VERSION "dbc-export 1 2026.26.6.5"

NS_ :

BS_:

BU_: ADSP APB APP APS APSB BB BMS CC CMP CMPD CP DAS DI DIF DIR DPB EPAS3P EPAS3S EPASTP EPASTS EPBL EPBR ESP EVSE FC GTW HCML HCMR HVP IBST ICR IDB LS OCS1P PARK PCS PCS2 PM PMF PMR PNCD PTC RADC RCM RCM2 RCM3 RCU SCCM SCM SCS SDCR TAS TCU TCU2 TPMS TRCM UI UIS UMC USM V2G VC VCBATT VCBATT0 VCBATT1 VCBATT2 VCCC VCFRONT VCFRONT1 VCFRONT2 VCLEFT VCRIGHT VCSEAT2L VCSEAT2R VCSEC VEH

BO_ 505 VCSEC_requests: 8 VCSEC
 SG_ VCSEC_chargePortRequest : 0|2@1+ (1,0) [0|3] "" Vector__XXX
 SG_ VCSEC_presentHandles : 4|1@1+ (1,0) [0|1] "" Vector__XXX
 SG_ VCSEC_frontLeftClosureRequest : 5|3@1+ (1,0) [0|7] "" Vector__XXX
 SG_ VCSEC_frontRightClosureRequest : 8|3@1+ (1,0) [0|7] "" Vector__XXX
 SG_ VCSEC_rearLeftClosureRequest : 11|3@1+ (1,0) [0|7] "" Vector__XXX
 SG_ VCSEC_rearRightClosureRequest : 14|3@1+ (1,0) [0|7] "" Vector__XXX
 SG_ VCSEC_rearTrunkClosureRequest : 17|3@1+ (1,0) [0|7] "" Vector__XXX
 SG_ VCSEC_frontLeftRequestReason : 20|3@1+ (1,0) [0|7] "" Vector__XXX
 SG_ VCSEC_frontRightRequestReason : 23|3@1+ (1,0) [0|7] "" Vector__XXX
 SG_ VCSEC_rearLeftRequestReason : 26|3@1+ (1,0) [0|7] "" Vector__XXX
 SG_ VCSEC_rearRightRequestReason : 29|3@1+ (1,0) [0|7] "" Vector__XXX
 SG_ VCSEC_rearTrunkRequestReason : 32|3@1+ (1,0) [0|7] "" Vector__XXX
 SG_ VCSEC_rdMapDumpRequested : 35|1@1+ (1,0) [0|1] "" Vector__XXX
 SG_ VCSEC_driveAttemptedWithoutAuth : 36|4@1+ (1,0) [0|15] "" Vector__XXX
 SG_ VCSEC_closeAllStatus : 41|2@1+ (1,0) [0|3] "" Vector__XXX
 SG_ VCSEC_snapshotRequested : 43|4@1+ (1,0) [0|15] "" Vector__XXX
 SG_ VCSEC_chargeportRequestReason : 47|3@1+ (1,0) [0|7] "" Vector__XXX
 SG_ VCSEC_frontTrunkClosureRequest : 51|3@1+ (1,0) [0|7] "" Vector__XXX
 SG_ VCSEC_frontTrunkRequestReason : 54|3@1+ (1,0) [0|7] "" Vector__XXX

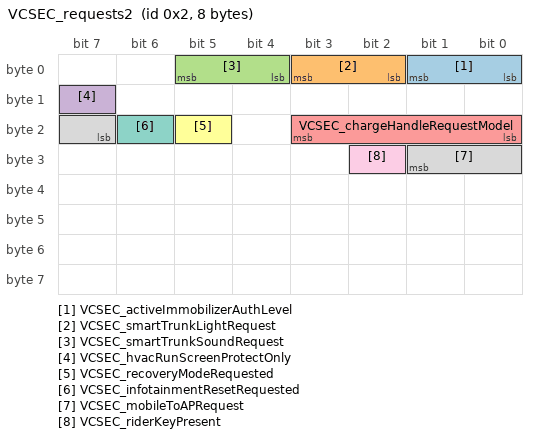
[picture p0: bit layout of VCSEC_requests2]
BO_ 2 VCSEC_requests2: 8 VCSEC
 SG_ VCSEC_activeImmobilizerAuthLevel : 0|2@1+ (1,0) [0|3] "" Vector__XXX
 SG_ VCSEC_smartTrunkLightRequest : 2|2@1+ (1,0) [0|3] "" Vector__XXX
 SG_ VCSEC_smartTrunkSoundRequest : 4|2@1+ (1,0) [0|3] "" Vector__XXX
 SG_ VCSEC_hvacRunScreenProtectOnly : 15|1@1+ (1,0) [0|1] "" Vector__XXX
 SG_ VCSEC_chargeHandleRequestModel : 16|4@1+ (1,0) [0|15] "" Vector__XXX
 SG_ VCSEC_recoveryModeRequested : 21|1@1+ (1,0) [0|1] "" Vector__XXX
 SG_ VCSEC_infotainmentResetRequested : 22|1@1+ (1,0) [0|1] "" Vector__XXX
 SG_ VCSEC_mobileToAPRequest : 23|3@1+ (1,0) [0|7] "" Vector__XXX
 SG_ VCSEC_riderKeyPresent : 26|1@1+ (1,0) [0|1] "" Vector__XXX

BO_ 1850 VC_LVBMS_brickMeasurements: 8 VC
 SG_ VC_LVBMS_brickMeasurementsMultip M : 0|6@1+ (1,0) [0|63] "" Vector__XXX
 SG_ VC_LVBMS_brickVoltage1 m0 : 8|13@1+ (0.001,0) [0|6.535] "V" Vector__XXX
 SG_ VC_LVBMS_brickVoltage2 m0 : 24|13@1+ (0.001,0) [0|6.535] "V" Vector__XXX
 SG_ VC_LVBMS_brickVoltage3 m0 : 37|13@1+ (0.001,0) [0|6.535] "V" Vector__XXX
 SG_ VC_LVBMS_brickVoltage4 m0 : 50|13@1+ (0.001,0) [0|6.535] "V" Vector__XXX
 SG_ VC_LVBMS_brickBalancingAh1 m1 : 8|24@1+ (0.001,0) [0|16777.214] "Ah" Vector__XXX
 SG_ VC_LVBMS_brickBalancingAh2 m1 : 32|24@1+ (0.001,0) [0|16777.214] "Ah" Vector__XXX
 SG_ VC_LVBMS_brickBalancingState1 m1 : 56|1@1+ (1,0) [0|1] "" Vector__XXX
 SG_ VC_LVBMS_brickBalancingState2 m1 : 57|1@1+ (1,0) [0|1] "" Vector__XXX
 SG_ VC_LVBMS_brickBalancingAh3 m2 : 8|24@1+ (0.001,0) [0|16777.214] "Ah" Vector__XXX
 SG_ VC_LVBMS_brickBalancingAh4 m2 : 32|24@1+ (0.001,0) [0|16777.214] "Ah" Vector__XXX
 SG_ VC_LVBMS_brickBalancingState3 m2 : 56|1@1+ (1,0) [0|1] "" Vector__XXX
 SG_ VC_LVBMS_brickBalancingState4 m2 : 57|1@1+ (1,0) [0|1] "" Vector__XXX

BO_ 1655 VC_LVBMS_statusHigh: 8 VC
 SG_ VC_lvbmsStatusHighIndex M : 0|3@1+ (1,0) [0|7] "" Vector__XXX
 SG_ VC_LVBMS_packCurrent m0 : 3|22@1+ (0.001,-2000) [-2000|2194.302] "A" Vector__XXX
 SG_ VC_LVBMS_packVoltage m0 : 25|16@1+ (0.001,0) [0|65.534] "V" Vector__XXX
 SG_ VC_LVBMS_packTemperature m0 : 41|9@1+ (0.5,-50) [-50|205] "degC" Vector__XXX
 SG_ VC_LVBMS_MOSTemperature m0 : 50|12@1+ (0.5,-50) [-50|1997] "degC" Vector__XXX
 SG_ VC_LVBMS_sumCellVoltage m1 : 8|16@1+ (0.001,0) [0|65.534] "V" Vector__XXX
 SG_ VC_LVBMS_maxBrickVoltage m1 : 24|13@1+ (0.001,0) [0|8.19] "V" Vector__XXX
 SG_ VC_LVBMS_maxBrickVoltageIndex m1 : 40|8@1+ (1,0) [0|255] "" Vector__XXX
 SG_ VC_totalLVLoadCurrent m2 : 8|14@1- (0.1,0) [-200|400] "A" Vector__XXX
 SG_ VC_LVPackChargeCurrentLimit m2 : 22|12@1+ (0.1,0) [0|400] "A" Vector__XXX
 SG_ VC_LVPackCurrent m2 : 34|14@1- (0.1,0) [-200|400] "A" Vector__XXX
 SG_ VC_LVBMS_estimatedPackOcv m2 : 48|16@1+ (0.001,0) [0|65.535] "V" Vector__XXX
 SG_ VC_LVBMS_voltageTarget m3 : 3|16@1+ (0.001,0) [0|65.535] "V" Vector__XXX
 SG_ VC_LVBMS_currentTarget m3 : 19|18@1+ (0.001,-122) [-120|120] "A" Vector__XXX
 SG_ VC_LVBMS_maxAllowedChargeCurrent m3 : 37|13@1+ (0.1,0) [0|819] "A" Vector__XXX
 SG_ VC_LVBMS_maxAllowedDischargeCurr m3 : 50|13@1+ (0.1,0) [0|819] "A" Vector__XXX
 SG_ VC_LVBMS_MOSCommand m4 : 3|1@1+ (1,0) [0|1] "" Vector__XXX
 SG_ VC_LVBMS_ClearErrorCntrCommand m4 : 4|1@1+ (1,0) [0|1] "" Vector__XXX
 SG_ VC_LVBMS_ClearHistoricFaultComma m4 : 5|1@1+ (1,0) [0|1] "" Vector__XXX
 SG_ VC_LVBMS_ResetLVBMSCommand m4 : 6|1@1+ (1,0) [0|1] "" Vector__XXX
 SG_ VC_LVBMS_EnterHibernationCommand m4 : 7|1@1+ (1,0) [0|1] "" Vector__XXX
 SG_ VC_LVBMS_ECPAState m4 : 8|2@1+ (1,0) [0|3] "" Vector__XXX
 SG_ VC_LVBMS_MOSState m4 : 10|2@1+ (1,0) [0|3] "" Vector__XXX
 SG_ VC_LVBMS_VehicleState m4 : 12|2@1+ (1,0) [0|3] "" Vector__XXX
 SG_ VC_LVBMS_LINWakeDisabled m4 : 14|1@1+ (1,0) [0|1] "" Vector__XXX
 SG_ VC_LVBMS_chargeType m4 : 16|3@1+ (1,0) [0|7] "" Vector__XXX
 SG_ VC_LVBMS_cellAndArcProtEnabled m4 : 19|1@1+ (1,0) [0|1] "" Vector__XXX
 SG_ VC_LVBMS_avgBrickVoltage m4 : 24|13@1+ (0.001,0) [0|8.19] "V" Vector__XXX
 SG_ VC_LVBMS_minBrickVoltage m4 : 40|13@1+ (0.001,0) [0|8.19] "V" Vector__XXX
 SG_ VC_LVBMS_minBrickVoltageIndex m4 : 56|8@1+ (1,0) [0|255] "" Vector__XXX

BO_ 1816 VC_LVBMS_statusLow: 8 VC
 SG_ VC_lvbmsStatusLowIndex M : 0|3@1+ (1,0) [0|7] "" Vector__XXX
 SG_ VC_LVBMS_SOC m0 : 3|10@1+ (0.1,0) [0|102.2] "%" Vector__XXX
 SG_ VC_LVBMS_SOE m0 : 16|7@1+ (1,0) [0|126] "%" Vector__XXX
 SG_ VC_LVBMS_SOH m0 : 24|7@1+ (1,0) [0|126] "%" Vector__XXX
 SG_ VC_LVBMS_CellOVLevel1 m0 : 31|1@1+ (1,0) [0|1] "" Vector__XXX
 SG_ VC_LVBMS_CellOVLevel2 m0 : 32|1@1+ (1,0) [0|1] "" Vector__XXX
 SG_ VC_LVBMS_CellOVLevel3 m0 : 33|1@1+ (1,0) [0|1] "" Vector__XXX
 SG_ VC_LVBMS_CellUVLevel1 m0 : 34|1@1+ (1,0) [0|1] "" Vector__XXX
 SG_ VC_LVBMS_CellUVLevel2 m0 : 35|1@1+ (1,0) [0|1] "" Vector__XXX
 SG_ VC_LVBMS_ModuleOTLevel1 m0 : 36|1@1+ (1,0) [0|1] "" Vector__XXX
 SG_ VC_LVBMS_PackOVLevel1 m0 : 37|1@1+ (1,0) [0|1] "" Vector__XXX
 SG_ VC_LVBMS_PackOVLevel2 m0 : 38|1@1+ (1,0) [0|1] "" Vector__XXX
 SG_ VC_LVBMS_DischrgOCLevel1 m0 : 39|1@1+ (1,0) [0|1] "" Vector__XXX
 SG_ VC_LVBMS_DischrgOCLevel2 m0 : 40|1@1+ (1,0) [0|1] "" Vector__XXX
 SG_ VC_LVBMS_ChrgOCLevel1 m0 : 41|1@1+ (1,0) [0|1] "" Vector__XXX
 SG_ VC_LVBMS_ChrgOCLevel2 m0 : 42|1@1+ (1,0) [0|1] "" Vector__XXX
 SG_ VC_LVBMS_MOSFETOTLevel1 m0 : 43|1@1+ (1,0) [0|1] "" Vector__XXX
 SG_ VC_LVBMS_KBValueLostFault m0 : 44|1@1+ (1,0) [0|1] "" Vector__XXX
 SG_ VC_LVBMS_BalanceCircuitFault m0 : 45|1@1+ (1,0) [0|1] "" Vector__XXX
 SG_ VC_LVBMS_MOSStateFault m0 : 46|1@1+ (1,0) [0|1] "" Vector__XXX
 SG_ VC_LVBMS_NTCTempDiffWarnLevel1 m0 : 47|1@1+ (1,0) [0|1] "" Vector__XXX
 SG_ VC_LVBMS_DeepDischargeFlag m0 : 48|1@1+ (1,0) [0|1] "" Vector__XXX
 SG_ VC_LVBMS_SamplingError m0 : 49|1@1+ (1,0) [0|1] "" Vector__XXX
 SG_ VC_LVBMS_MosfetStuckCloseError m0 : 50|1@1+ (1,0) [0|1] "" Vector__XXX
 SG_ VC_LVBMS_MosfetStuckOpenError m0 : 51|1@1+ (1,0) [0|1] "" Vector__XXX
 SG_ VC_LVBMS_AvgSleepCurrent m1 : 8|16@1+ (0.01,-200) [-200|455.34] "A" Vector__XXX
 SG_ VC_LVBMS_TimeSlept m1 : 24|24@1+ (1,0) [0|16777214] "min" Vector__XXX
 SG_ VC_LVBMS_SOP m1 : 48|8@1+ (20,0) [0|5080] "W" Vector__XXX
 SG_ VC_LVBMS_AhCharged m2 : 8|32@1+ (0.001,0) [0|4294967.294] "Ah" Vector__XXX
 SG_ VC_LVBMS_MinSleepCurrent m2 : 40|16@1+ (0.01,-200) [-200|455.34] "A" Vector__XXX
 SG_ VC_LVBMS_AhDischarged m3 : 8|32@1+ (0.001,0) [0|4294967.294] "Ah" Vector__XXX
 SG_ VC_LVBMS_MaxSleepCurrent m3 : 40|16@1+ (0.01,-200) [-200|455.34] "A" Vector__XXX
 SG_ VC_LVBMS_sumCellVoltageFiltered m4 : 8|16@1+ (0.001,0) [0|65.534] "V" Vector__XXX
 SG_ VC_LVBMS_maxCellSOC m4 : 24|10@1+ (0.1,0) [0|102.2] "%" Vector__XXX
 SG_ VC_LVBMS_minCellSOC m4 : 34|10@1+ (0.1,0) [0|102.2] "%" Vector__XXX
 SG_ VC_LVBMS_staticSOCCorrection m4 : 44|1@1+ (1,0) [0|1] "" Vector__XXX
 SG_ VC_LVBMS_dynamicSOCCorrection m4 : 45|1@1+ (1,0) [0|1] "" Vector__XXX
 SG_ VC_LVBMS_usableEnergyAvailable m4 : 48|12@1+ (1,0) [0|4000] "Wh" Vector__XXX
 SG_ VC_LVBMS_brakeTelltale m4 : 60|2@1+ (1,0) [0|3] "" Vector__XXX

BO_ 1089 VC_pcsInterface: 8 VC
 SG_ VC_pcsInterfaceMuxIndex M : 48|1@1+ (1,0) [0|1] "" Vector__XXX
 SG_ VC_pcsInterfaceCounter : 50|4@1+ (1,0) [0|15] "" Vector__XXX
 SG_ VC_pcsInterfaceChecksum : 56|8@1+ (1,0) [0|255] "" Vector__XXX
 SG_ VC_pcsLVVoltageTarget m0 : 0|13@1+ (0.01,0) [0|65.535] "V" Vector__XXX
 SG_ VC_pcsLVMinVoltageLimit m0 : 13|13@1+ (0.01,0) [0|65.535] "V" Vector__XXX
 SG_ VC_pcsLVMaxVoltageLimit m0 : 27|13@1+ (0.01,0) [0|65.535] "V" Vector__XXX
 SG_ VC_goodForPCSPowerCycle m0 : 46|1@1+ (1,0) [0|1] "" Vector__XXX
 SG_ VC_LVBatteryCannotSupportVehicle m0 : 47|1@1+ (1,0) [0|1] "" Vector__XXX
 SG_ VC_pcsResistanceFiltered m1 : 0|16@1+ (0.01,0) [0|655.34] "mOhm" Vector__XXX
 SG_ VC_pcsLVMaxDchrgCurrentLimit m1 : 16|12@1+ (0.1,0) [0|400] "A" Vector__XXX
 SG_ VC_defaultPcsLVVoltageTarget m1 : 28|13@1+ (0.01,0) [0|65.535] "V" Vector__XXX
 SG_ VC_lvHwProtSelfTestActive m1 : 41|1@1+ (1,0) [0|1] "" Vector__XXX
 SG_ VC_lvBatteryDischargeRequest m1 : 42|1@1+ (1,0) [0|1] "" Vector__XXX

BO_ 1091 VC_pcsManagement: 8 VC
 SG_ VC_pcsManagementChecksum : 0|8@1+ (1,0) [0|255] "" Vector__XXX
 SG_ VC_pcsManagementCounter : 8|4@1+ (1,0) [0|15] "" Vector__XXX
 SG_ VC_pcsManagementMuxIndex M : 12|1@1+ (1,0) [0|1] "" Vector__XXX
 SG_ VC_dcdcLVVoltageTargetMax m0 : 16|10@1+ (0.1,0) [0|102.3] "V" Vector__XXX
 SG_ VC_dcdcLVVoltageTargetMin m0 : 26|10@1+ (0.1,0) [0|102.3] "V" Vector__XXX
 SG_ VC_dcdcLVInputPowerLimit m0 : 36|8@1+ (50,0) [0|12750] "W" Vector__XXX

BO_ 1107 VEH_billing: 8 VEH
 SG_ VEH_pricebookId : 0|32@1+ (1,0) [0|4294967295] "" Vector__XXX

BO_ 1651 VEH_isoTpToEvse: 8 VEH
 SG_ VEH_isoTpToEvseData : 0|64@1+ (1,0) [0|1.84467440737e+19] "" Vector__XXX

CM_ BO_ 505 "Vehicle security controller message: requests";
CM_ SG_ 505 VCSEC_chargePortRequest "Open and close requests of the charge port door.";
CM_ SG_ 505 VCSEC_presentHandles "VCSEC command to present the handles. Applicable to Model S.";
CM_ SG_ 505 VCSEC_frontLeftClosureRequest "VCSEC command to present the front left door.";
CM_ SG_ 505 VCSEC_frontRightClosureRequest "VCSEC command to present the front right door.";
CM_ SG_ 505 VCSEC_rearLeftClosureRequest "open and close requests of the left rear door.";
CM_ SG_ 505 VCSEC_rearRightClosureRequest "open and close requests of the right rear door.";
CM_ SG_ 505 VCSEC_rearTrunkClosureRequest "VCSEC command to operate the rear trunk.";
CM_ SG_ 505 VCSEC_frontLeftRequestReason "VCSEC reason to present the front left door.";
CM_ SG_ 505 VCSEC_frontRightRequestReason "VCSEC reason to present the front right door.";
CM_ SG_ 505 VCSEC_rearLeftRequestReason "open and close request reason of the left rear door.";
CM_ SG_ 505 VCSEC_rearRightRequestReason "open and close request reason of the right rear door.";
CM_ SG_ 505 VCSEC_rearTrunkRequestReason "VCSEC reason for command to operate the rear trunk.";
CM_ SG_ 505 VCSEC_rdMapDumpRequested "Vehicle security controller: rd map dump requested";
CM_ SG_ 505 VCSEC_driveAttemptedWithoutAuth "Driver is attempting shift into drive wihout a key present";
CM_ SG_ 505 VCSEC_closeAllStatus "Vehicle security controller: close all status";
CM_ SG_ 505 VCSEC_snapshotRequested "Vehicle security controller: snapshot requested";
CM_ SG_ 505 VCSEC_chargeportRequestReason "VCSEC reason to open the chargeport door.";
CM_ SG_ 505 VCSEC_frontTrunkClosureRequest "VCSEC command to operate front trunk.";
CM_ SG_ 505 VCSEC_frontTrunkRequestReason "VCSEC reason to present the front left door.";
CM_ BO_ 2 "Vehicle security controller message: requests2";
CM_ SG_ 2 VCSEC_activeImmobilizerAuthLevel "The level of auth VCSEC will respond with when the Drive Inverter asks for auth";
CM_ SG_ 2 VCSEC_smartTrunkLightRequest "Request to signal indication lights for the smart trunk feature";
CM_ SG_ 2 VCSEC_smartTrunkSoundRequest "Vehicle security controller: smart trunk sound request";
CM_ SG_ 2 VCSEC_hvacRunScreenProtectOnly "Vehicle security controller: hvac run screen protect only";
CM_ SG_ 2 VCSEC_chargeHandleRequestModel "Vehicle security controller: charge handle request model";
CM_ SG_ 2 VCSEC_recoveryModeRequested "Vehicle security controller: recovery mode requested";
CM_ SG_ 2 VCSEC_infotainmentResetRequested "Vehicle security controller: infotainment reset requested";
CM_ SG_ 2 VCSEC_mobileToAPRequest "Vehicle security controller: mobile to AP request";
CM_ SG_ 2 VCSEC_riderKeyPresent "Vehicle security controller: rider key present";
CM_ BO_ 1850 "VC ECU message: LVBMS brick measurements";
CM_ SG_ 1850 VC_LVBMS_brickMeasurementsMultip "VC ECU: LVBMS brick measurements multiplexer";
CM_ SG_ 1850 VC_LVBMS_brickVoltage1 "Voltage of a low voltage battery brick";
CM_ SG_ 1850 VC_LVBMS_brickVoltage2 "Voltage of a low voltage battery brick";
CM_ SG_ 1850 VC_LVBMS_brickVoltage3 "Voltage of a low voltage battery brick";
CM_ SG_ 1850 VC_LVBMS_brickVoltage4 "Voltage of a low voltage battery brick";
CM_ SG_ 1850 VC_LVBMS_brickBalancingAh1 "Ah count of a low voltage battery brick";
CM_ SG_ 1850 VC_LVBMS_brickBalancingAh2 "Ah count of a low voltage battery brick";
CM_ SG_ 1850 VC_LVBMS_brickBalancingState1 "VC ECU: LVBMS brick balancing state1";
CM_ SG_ 1850 VC_LVBMS_brickBalancingState2 "VC ECU: LVBMS brick balancing state2";
CM_ SG_ 1850 VC_LVBMS_brickBalancingAh3 "Ah count of a low voltage battery brick";
CM_ SG_ 1850 VC_LVBMS_brickBalancingAh4 "Ah count of a low voltage battery brick";
CM_ SG_ 1850 VC_LVBMS_brickBalancingState3 "VC ECU: LVBMS brick balancing state3";
CM_ SG_ 1850 VC_LVBMS_brickBalancingState4 "VC ECU: LVBMS brick balancing state4";
CM_ BO_ 1655 "VC ECU message: LVBMS status high";
CM_ SG_ 1655 VC_lvbmsStatusHighIndex "VC ECU: lvbms status high index";
CM_ SG_ 1655 VC_LVBMS_packCurrent "Electrical current into the low voltage battery";
CM_ SG_ 1655 VC_LVBMS_packVoltage "Voltage of the low voltage battery";
CM_ SG_ 1655 VC_LVBMS_packTemperature "Temperature of the low voltage battery";
CM_ SG_ 1655 VC_LVBMS_MOSTemperature "Temperature of the MOSFET on the low voltage battery";
CM_ SG_ 1655 VC_LVBMS_sumCellVoltage "Sum of the cell voltage of the low voltage battery";
CM_ SG_ 1655 VC_LVBMS_maxBrickVoltage "Maximum cell voltage in the low voltage battery";
CM_ SG_ 1655 VC_LVBMS_maxBrickVoltageIndex "VC ECU: LVBMS max brick voltage index";
CM_ SG_ 1655 VC_totalLVLoadCurrent "Total LV load current of the vehicle.";
CM_ SG_ 1655 VC_LVPackChargeCurrentLimit "Charge current limit for the LV battery pack.";
CM_ SG_ 1655 VC_LVPackCurrent "Current of the LV battery pack.";
CM_ SG_ 1655 VC_LVBMS_estimatedPackOcv "VC ECU: LVBMS estimated pack ocv";
CM_ SG_ 1655 VC_LVBMS_voltageTarget "Voltage target of the LV battery";
CM_ SG_ 1655 VC_LVBMS_currentTarget "Target current requested by the LV battery";
CM_ SG_ 1655 VC_LVBMS_maxAllowedChargeCurrent "Maximum allowed charge current of the battery";
CM_ SG_ 1655 VC_LVBMS_maxAllowedDischargeCurr "Maximum allowed discharge current of the battery";
CM_ SG_ 1655 VC_LVBMS_MOSCommand "Current state of the MOS command to the LV battery";
CM_ SG_ 1655 VC_LVBMS_ClearErrorCntrCommand "VC ECU: LVBMS clear error cntr command";
CM_ SG_ 1655 VC_LVBMS_ClearHistoricFaultComma "VC ECU: LVBMS clear historic fault command";
CM_ SG_ 1655 VC_LVBMS_ResetLVBMSCommand "Reset command issued to LVBMS, commanded by VC";
CM_ SG_ 1655 VC_LVBMS_EnterHibernationCommand "VC ECU: LVBMS enter hibernation command";
CM_ SG_ 1655 VC_LVBMS_ECPAState "Current state of the E-CPA on the LV battery";
CM_ SG_ 1655 VC_LVBMS_MOSState "Current state of the MOS on the LV battery";
CM_ SG_ 1655 VC_LVBMS_VehicleState "VC ECU: LVBMS vehicle state";
CM_ SG_ 1655 VC_LVBMS_LINWakeDisabled "VC ECU: LVBMS LIN wake disabled";
CM_ SG_ 1655 VC_LVBMS_chargeType "VC ECU: LVBMS charge type";
CM_ SG_ 1655 VC_LVBMS_cellAndArcProtEnabled "Indicates whether the VC has commanded cell protections to be active";
CM_ SG_ 1655 VC_LVBMS_avgBrickVoltage "Average voltage of all cells in the low voltage battery";
CM_ SG_ 1655 VC_LVBMS_minBrickVoltage "Minimum cell voltage in the low voltage battery";
CM_ SG_ 1655 VC_LVBMS_minBrickVoltageIndex "VC ECU: LVBMS min brick voltage index";
CM_ BO_ 1816 "VC ECU message: LVBMS status low";
CM_ SG_ 1816 VC_lvbmsStatusLowIndex "VC ECU: lvbms status low index";
CM_ SG_ 1816 VC_LVBMS_SOC "State of charge reported by the low voltage battery sensor";
CM_ SG_ 1816 VC_LVBMS_SOE "State of energy reported by the low voltage battery";
CM_ SG_ 1816 VC_LVBMS_SOH "State of health reported by the low voltage battery";
CM_ SG_ 1816 VC_LVBMS_CellOVLevel1 "VC ECU: LVBMS cell OV level1";
CM_ SG_ 1816 VC_LVBMS_CellOVLevel2 "VC ECU: LVBMS cell OV level2";
CM_ SG_ 1816 VC_LVBMS_CellOVLevel3 "VC ECU: LVBMS cell OV level3";
CM_ SG_ 1816 VC_LVBMS_CellUVLevel1 "VC ECU: LVBMS cell UV level1";
CM_ SG_ 1816 VC_LVBMS_CellUVLevel2 "VC ECU: LVBMS cell UV level2";
CM_ SG_ 1816 VC_LVBMS_ModuleOTLevel1 "VC ECU: LVBMS module OT level1";
CM_ SG_ 1816 VC_LVBMS_PackOVLevel1 "VC ECU: LVBMS pack OV level1";
CM_ SG_ 1816 VC_LVBMS_PackOVLevel2 "Pack Over Voltage Level 2 flag status";
CM_ SG_ 1816 VC_LVBMS_DischrgOCLevel1 "VC ECU: LVBMS dischrg OC level1";
CM_ SG_ 1816 VC_LVBMS_DischrgOCLevel2 "Discharge Over Current Level 2 flag status";
CM_ SG_ 1816 VC_LVBMS_ChrgOCLevel1 "VC ECU: LVBMS chrg OC level1";
CM_ SG_ 1816 VC_LVBMS_ChrgOCLevel2 "Charge Over Current Level 2 flag status";
CM_ SG_ 1816 VC_LVBMS_MOSFETOTLevel1 "VC ECU: LVBMS MOSFETOT level1";
CM_ SG_ 1816 VC_LVBMS_KBValueLostFault "Loss of CATL specific internal value flag status. Lost value causes offset in current sensor reading.";
CM_ SG_ 1816 VC_LVBMS_BalanceCircuitFault "Balance Circuit Fault flag status";
CM_ SG_ 1816 VC_LVBMS_MOSStateFault "Mosfet fault state flag status. Not to be confused with VC_LVBMS_MOSState.";
CM_ SG_ 1816 VC_LVBMS_NTCTempDiffWarnLevel1 "VC ECU: LVBMS NTC temp diff warn level1";
CM_ SG_ 1816 VC_LVBMS_DeepDischargeFlag "Deep Discharge flag status";
CM_ SG_ 1816 VC_LVBMS_SamplingError "Sampling Error flag status";
CM_ SG_ 1816 VC_LVBMS_MosfetStuckCloseError "Mosfet Stuck Close flag status";
CM_ SG_ 1816 VC_LVBMS_MosfetStuckOpenError "Mosfet Stuck Open flag status";
CM_ SG_ 1816 VC_LVBMS_AvgSleepCurrent "Low voltage battery average sleep current.";
CM_ SG_ 1816 VC_LVBMS_TimeSlept "VC ECU: LVBMS time slept";
CM_ SG_ 1816 VC_LVBMS_SOP "VC ECU: LVBMS SOP";
CM_ SG_ 1816 VC_LVBMS_AhCharged "Low voltage battery charge state";
CM_ SG_ 1816 VC_LVBMS_MinSleepCurrent "VC ECU: LVBMS min sleep current";
CM_ SG_ 1816 VC_LVBMS_AhDischarged "Low voltage battery charge state";
CM_ SG_ 1816 VC_LVBMS_MaxSleepCurrent "VC ECU: LVBMS max sleep current";
CM_ SG_ 1816 VC_LVBMS_sumCellVoltageFiltered "VC ECU: LVBMS sum cell voltage filtered";
CM_ SG_ 1816 VC_LVBMS_maxCellSOC "SOC estimate of the highest SOC cell.";
CM_ SG_ 1816 VC_LVBMS_minCellSOC "SOC estimate of the lowest SOC cell.";
CM_ SG_ 1816 VC_LVBMS_staticSOCCorrection "Flag indicating the LVBMS is performing static SOC correction.";
CM_ SG_ 1816 VC_LVBMS_dynamicSOCCorrection "Flag indicating the LVBMS is performing dynamic SOC correction.";
CM_ SG_ 1816 VC_LVBMS_usableEnergyAvailable "Available/remaining usable pack energy";
CM_ SG_ 1816 VC_LVBMS_brakeTelltale "VC ECU: LVBMS brake telltale";
CM_ BO_ 1089 "VC ECU message: pcs interface";
CM_ SG_ 1089 VC_pcsInterfaceMuxIndex "VC ECU: pcs interface mux index";
CM_ SG_ 1089 VC_pcsInterfaceCounter "VC ECU: pcs interface counter";
CM_ SG_ 1089 VC_pcsInterfaceChecksum "VC ECU: pcs interface checksum";
CM_ SG_ 1089 VC_pcsLVVoltageTarget "VC ECU: pcs LV voltage target";
CM_ SG_ 1089 VC_pcsLVMinVoltageLimit "VC ECU: pcs LV min voltage limit";
CM_ SG_ 1089 VC_pcsLVMaxVoltageLimit "VC ECU: pcs LV max voltage limit";
CM_ SG_ 1089 VC_goodForPCSPowerCycle "VC ECU: good for PCS power cycle";
CM_ SG_ 1089 VC_LVBatteryCannotSupportVehicle "VC ECU: LV battery cannot support vehicle";
CM_ SG_ 1089 VC_pcsResistanceFiltered "VC ECU: pcs resistance filtered";
CM_ SG_ 1089 VC_pcsLVMaxDchrgCurrentLimit "VC ECU: pcs LV max dchrg current limit";
CM_ SG_ 1089 VC_defaultPcsLVVoltageTarget "VC ECU: default pcs LV voltage target";
CM_ SG_ 1089 VC_lvHwProtSelfTestActive "Reports whether Low Voltage (LV) Hardware (HW) protection self-tests are running or about to run due to a retry.";
CM_ SG_ 1089 VC_lvBatteryDischargeRequest "VC ECU: lv battery discharge request";
CM_ BO_ 1091 "VC ECU message: pcs management";
CM_ SG_ 1091 VC_pcsManagementChecksum "VC ECU: pcs management checksum";
CM_ SG_ 1091 VC_pcsManagementCounter "VC ECU: pcs management counter";
CM_ SG_ 1091 VC_pcsManagementMuxIndex "VC ECU: pcs management mux index";
CM_ SG_ 1091 VC_dcdcLVVoltageTargetMax "VC ECU: dcdc LV voltage target max";
CM_ SG_ 1091 VC_dcdcLVVoltageTargetMin "VC ECU: dcdc LV voltage target min";
CM_ SG_ 1091 VC_dcdcLVInputPowerLimit "VC ECU: dcdc LV input power limit";
CM_ BO_ 1107 "VEH ECU message: billing";
CM_ SG_ 1107 VEH_pricebookId "VEH ECU: pricebook id";
CM_ BO_ 1651 "VEH ECU message: iso tp to evse";
CM_ SG_ 1651 VEH_isoTpToEvseData "VEH ECU: iso tp to evse data";
BA_DEF_ BO_ "GenMsgCycleTime" INT 0 3600000;
BA_DEF_ BO_ "GenMsgSendType" ENUM "Cyclic","NotUsed","NotUsed","NotUsed","NotUsed","NotUsed","NotUsed","IfActive","NoMsgSendType","NotUsed";
BA_DEF_ BO_ "VFrameFormat" ENUM "StandardCAN","ExtendedCAN","reserved","J1939PG","reserved","reserved","reserved","reserved","reserved","reserved","reserved","reserved","reserved","reserved","StandardCAN_FD","ExtendedCAN_FD";
BA_DEF_ BO_ "CANFD_BRS" ENUM "0","1";
BA_DEF_ SG_ "SystemSignalLongSymbol" STRING;
BA_DEF_ SG_ "Confidence" ENUM "layout-only","plausible","validated";
BA_DEF_DEF_ "GenMsgCycleTime" 0;
BA_DEF_DEF_ "GenMsgSendType" "NoMsgSendType";
BA_DEF_DEF_ "VFrameFormat" "StandardCAN";
BA_DEF_DEF_ "CANFD_BRS" "1";
BA_DEF_DEF_ "SystemSignalLongSymbol" "";
BA_DEF_DEF_ "Confidence" "layout-only";
BA_ "Confidence" SG_ 505 VCSEC_chargePortRequest 1;
BA_ "Confidence" SG_ 505 VCSEC_presentHandles 1;
BA_ "Confidence" SG_ 505 VCSEC_frontLeftClosureRequest 1;
BA_ "Confidence" SG_ 505 VCSEC_frontRightClosureRequest 1;
BA_ "Confidence" SG_ 505 VCSEC_rearLeftClosureRequest 1;
BA_ "Confidence" SG_ 505 VCSEC_rearRightClosureRequest 1;
BA_ "Confidence" SG_ 505 VCSEC_rearTrunkClosureRequest 1;
BA_ "Confidence" SG_ 505 VCSEC_frontLeftRequestReason 1;
BA_ "Confidence" SG_ 505 VCSEC_frontRightRequestReason 1;
BA_ "Confidence" SG_ 505 VCSEC_rearLeftRequestReason 1;
BA_ "Confidence" SG_ 505 VCSEC_rearRightRequestReason 1;
BA_ "Confidence" SG_ 505 VCSEC_rearTrunkRequestReason 1;
BA_ "Confidence" SG_ 505 VCSEC_driveAttemptedWithoutAuth 1;
BA_ "Confidence" SG_ 505 VCSEC_closeAllStatus 1;
BA_ "Confidence" SG_ 505 VCSEC_snapshotRequested 1;
BA_ "Confidence" SG_ 505 VCSEC_chargeportRequestReason 1;
BA_ "Confidence" SG_ 505 VCSEC_frontTrunkClosureRequest 1;
BA_ "Confidence" SG_ 505 VCSEC_frontTrunkRequestReason 1;
BA_ "Confidence" SG_ 2 VCSEC_activeImmobilizerAuthLevel 1;
BA_ "Confidence" SG_ 2 VCSEC_smartTrunkLightRequest 1;
BA_ "Confidence" SG_ 2 VCSEC_smartTrunkSoundRequest 1;
BA_ "Confidence" SG_ 2 VCSEC_chargeHandleRequestModel 1;
BA_ "Confidence" SG_ 2 VCSEC_mobileToAPRequest 1;
BA_ "SystemSignalLongSymbol" SG_ 1850 VC_LVBMS_brickMeasurementsMultip "VC_LVBMS_brickMeasurementsMultiplexer";
BA_ "Confidence" SG_ 1850 VC_LVBMS_brickVoltage1 1;
BA_ "Confidence" SG_ 1850 VC_LVBMS_brickVoltage2 1;
BA_ "Confidence" SG_ 1850 VC_LVBMS_brickVoltage3 1;
BA_ "Confidence" SG_ 1850 VC_LVBMS_brickVoltage4 1;
BA_ "Confidence" SG_ 1850 VC_LVBMS_brickBalancingAh1 1;
BA_ "Confidence" SG_ 1850 VC_LVBMS_brickBalancingAh2 1;
BA_ "Confidence" SG_ 1850 VC_LVBMS_brickBalancingState1 1;
BA_ "Confidence" SG_ 1850 VC_LVBMS_brickBalancingState2 1;
BA_ "Confidence" SG_ 1850 VC_LVBMS_brickBalancingAh3 1;
BA_ "Confidence" SG_ 1850 VC_LVBMS_brickBalancingAh4 1;
BA_ "Confidence" SG_ 1850 VC_LVBMS_brickBalancingState3 1;
BA_ "Confidence" SG_ 1850 VC_LVBMS_brickBalancingState4 1;
BA_ "Confidence" SG_ 1655 VC_LVBMS_packCurrent 1;
BA_ "Confidence" SG_ 1655 VC_LVBMS_packVoltage 1;
BA_ "Confidence" SG_ 1655 VC_LVBMS_packTemperature 1;
BA_ "Confidence" SG_ 1655 VC_LVBMS_MOSTemperature 1;
BA_ "Confidence" SG_ 1655 VC_LVBMS_sumCellVoltage 1;
BA_ "Confidence" SG_ 1655 VC_LVBMS_maxBrickVoltage 1;
BA_ "Confidence" SG_ 1655 VC_totalLVLoadCurrent 1;
BA_ "Confidence" SG_ 1655 VC_LVPackChargeCurrentLimit 1;
BA_ "Confidence" SG_ 1655 VC_LVPackCurrent 1;
BA_ "Confidence" SG_ 1655 VC_LVBMS_estimatedPackOcv 1;
BA_ "Confidence" SG_ 1655 VC_LVBMS_voltageTarget 1;
BA_ "Confidence" SG_ 1655 VC_LVBMS_currentTarget 1;
BA_ "Confidence" SG_ 1655 VC_LVBMS_maxAllowedChargeCurrent 1;
BA_ "Confidence" SG_ 1655 VC_LVBMS_maxAllowedDischargeCurr 1;
BA_ "SystemSignalLongSymbol" SG_ 1655 VC_LVBMS_maxAllowedDischargeCurr "VC_LVBMS_maxAllowedDischargeCurrent";
BA_ "Confidence" SG_ 1655 VC_LVBMS_MOSCommand 1;
BA_ "SystemSignalLongSymbol" SG_ 1655 VC_LVBMS_ClearHistoricFaultComma "VC_LVBMS_ClearHistoricFaultCommand";
BA_ "Confidence" SG_ 1655 VC_LVBMS_ResetLVBMSCommand 1;
BA_ "Confidence" SG_ 1655 VC_LVBMS_ECPAState 1;
BA_ "Confidence" SG_ 1655 VC_LVBMS_MOSState 1;
BA_ "Confidence" SG_ 1655 VC_LVBMS_VehicleState 1;
BA_ "Confidence" SG_ 1655 VC_LVBMS_LINWakeDisabled 1;
BA_ "Confidence" SG_ 1655 VC_LVBMS_chargeType 1;
BA_ "Confidence" SG_ 1655 VC_LVBMS_cellAndArcProtEnabled 1;
BA_ "Confidence" SG_ 1655 VC_LVBMS_avgBrickVoltage 1;
BA_ "Confidence" SG_ 1655 VC_LVBMS_minBrickVoltage 1;
BA_ "Confidence" SG_ 1816 VC_LVBMS_SOC 1;
BA_ "Confidence" SG_ 1816 VC_LVBMS_SOE 1;
BA_ "Confidence" SG_ 1816 VC_LVBMS_SOH 1;
BA_ "Confidence" SG_ 1816 VC_LVBMS_PackOVLevel2 1;
BA_ "Confidence" SG_ 1816 VC_LVBMS_DischrgOCLevel2 1;
BA_ "Confidence" SG_ 1816 VC_LVBMS_ChrgOCLevel2 1;
BA_ "Confidence" SG_ 1816 VC_LVBMS_KBValueLostFault 1;
BA_ "Confidence" SG_ 1816 VC_LVBMS_BalanceCircuitFault 1;
BA_ "Confidence" SG_ 1816 VC_LVBMS_MOSStateFault 1;
BA_ "Confidence" SG_ 1816 VC_LVBMS_DeepDischargeFlag 1;
BA_ "Confidence" SG_ 1816 VC_LVBMS_SamplingError 1;
BA_ "Confidence" SG_ 1816 VC_LVBMS_MosfetStuckCloseError 1;
BA_ "Confidence" SG_ 1816 VC_LVBMS_MosfetStuckOpenError 1;
BA_ "Confidence" SG_ 1816 VC_LVBMS_AvgSleepCurrent 1;
BA_ "Confidence" SG_ 1816 VC_LVBMS_TimeSlept 1;
BA_ "Confidence" SG_ 1816 VC_LVBMS_SOP 1;
BA_ "Confidence" SG_ 1816 VC_LVBMS_AhCharged 1;
BA_ "Confidence" SG_ 1816 VC_LVBMS_MinSleepCurrent 1;
BA_ "Confidence" SG_ 1816 VC_LVBMS_AhDischarged 1;
BA_ "Confidence" SG_ 1816 VC_LVBMS_MaxSleepCurrent 1;
BA_ "Confidence" SG_ 1816 VC_LVBMS_sumCellVoltageFiltered 1;
BA_ "Confidence" SG_ 1816 VC_LVBMS_maxCellSOC 1;
BA_ "Confidence" SG_ 1816 VC_LVBMS_minCellSOC 1;
BA_ "Confidence" SG_ 1816 VC_LVBMS_staticSOCCorrection 1;
BA_ "Confidence" SG_ 1816 VC_LVBMS_dynamicSOCCorrection 1;
BA_ "Confidence" SG_ 1816 VC_LVBMS_usableEnergyAvailable 1;
BA_ "Confidence" SG_ 1816 VC_LVBMS_brakeTelltale 1;
BA_ "Confidence" SG_ 1089 VC_pcsLVVoltageTarget 1;
BA_ "Confidence" SG_ 1089 VC_pcsLVMinVoltageLimit 1;
BA_ "Confidence" SG_ 1089 VC_pcsLVMaxVoltageLimit 1;
BA_ "Confidence" SG_ 1089 VC_pcsResistanceFiltered 1;
BA_ "Confidence" SG_ 1089 VC_pcsLVMaxDchrgCurrentLimit 1;
BA_ "Confidence" SG_ 1089 VC_defaultPcsLVVoltageTarget 1;
BA_ "Confidence" SG_ 1089 VC_lvHwProtSelfTestActive 1;
BA_ "Confidence" SG_ 1091 VC_dcdcLVVoltageTargetMax 1;
BA_ "Confidence" SG_ 1091 VC_dcdcLVVoltageTargetMin 1;
BA_ "Confidence" SG_ 1091 VC_dcdcLVInputPowerLimit 1;
VAL_ 505 VCSEC_chargePortRequest 3 "REQUEST_SNA" 2 "REQUEST_CLOSE" 1 "REQUEST_OPEN" 0 "REQUEST_NONE" ;
VAL_ 505 VCSEC_frontLeftClosureRequest 6 "POWERED_CLOSURE_REQUEST_CLOSE" 5 "POWERED_CLOSURE_REQUEST_OPEN_REDUCED" 4 "POWERED_CLOSURE_REQUEST_QUICK_OPEN" 3 "POWERED_CLOSURE_REQUEST_OPEN" 2 "POWERED_CLOSURE_REQUEST_STOP" 1 "POWERED_CLOSURE_REQUEST_MOVE" 0 "POWERED_CLOSURE_REQUEST_NONE" ;
VAL_ 505 VCSEC_frontRightClosureRequest 6 "POWERED_CLOSURE_REQUEST_CLOSE" 5 "POWERED_CLOSURE_REQUEST_OPEN_REDUCED" 4 "POWERED_CLOSURE_REQUEST_QUICK_OPEN" 3 "POWERED_CLOSURE_REQUEST_OPEN" 2 "POWERED_CLOSURE_REQUEST_STOP" 1 "POWERED_CLOSURE_REQUEST_MOVE" 0 "POWERED_CLOSURE_REQUEST_NONE" ;
VAL_ 505 VCSEC_rearLeftClosureRequest 6 "POWERED_CLOSURE_REQUEST_CLOSE" 5 "POWERED_CLOSURE_REQUEST_OPEN_REDUCED" 4 "POWERED_CLOSURE_REQUEST_QUICK_OPEN" 3 "POWERED_CLOSURE_REQUEST_OPEN" 2 "POWERED_CLOSURE_REQUEST_STOP" 1 "POWERED_CLOSURE_REQUEST_MOVE" 0 "POWERED_CLOSURE_REQUEST_NONE" ;
VAL_ 505 VCSEC_rearRightClosureRequest 6 "POWERED_CLOSURE_REQUEST_CLOSE" 5 "POWERED_CLOSURE_REQUEST_OPEN_REDUCED" 4 "POWERED_CLOSURE_REQUEST_QUICK_OPEN" 3 "POWERED_CLOSURE_REQUEST_OPEN" 2 "POWERED_CLOSURE_REQUEST_STOP" 1 "POWERED_CLOSURE_REQUEST_MOVE" 0 "POWERED_CLOSURE_REQUEST_NONE" ;
VAL_ 505 VCSEC_rearTrunkClosureRequest 6 "POWERED_CLOSURE_REQUEST_CLOSE" 5 "POWERED_CLOSURE_REQUEST_OPEN_REDUCED" 4 "POWERED_CLOSURE_REQUEST_QUICK_OPEN" 3 "POWERED_CLOSURE_REQUEST_OPEN" 2 "POWERED_CLOSURE_REQUEST_STOP" 1 "POWERED_CLOSURE_REQUEST_MOVE" 0 "POWERED_CLOSURE_REQUEST_NONE" ;
VAL_ 505 VCSEC_frontLeftRequestReason 7 "POWERED_CLOSURE_REQUEST_TAP_TO_OPEN" 6 "POWERED_CLOSURE_REQUEST_REASON_UI_REQUEST" 5 "POWERED_CLOSURE_REQUEST_UI_STOP_ALL" 4 "POWERED_CLOSURE_REQUEST_KEYFOB_UNLOCK_OPEN" 3 "POWERED_CLOSURE_REQUEST_REASON_AUTO_PRESENT" 2 "POWERED_CLOSURE_REQUEST_REASON_CLOSE_ALL" 1 "POWERED_CLOSURE_REQUEST_REASON_RKE" 0 "POWERED_CLOSURE_REQUEST_REASON_NONE" ;
VAL_ 505 VCSEC_frontRightRequestReason 7 "POWERED_CLOSURE_REQUEST_TAP_TO_OPEN" 6 "POWERED_CLOSURE_REQUEST_REASON_UI_REQUEST" 5 "POWERED_CLOSURE_REQUEST_UI_STOP_ALL" 4 "POWERED_CLOSURE_REQUEST_KEYFOB_UNLOCK_OPEN" 3 "POWERED_CLOSURE_REQUEST_REASON_AUTO_PRESENT" 2 "POWERED_CLOSURE_REQUEST_REASON_CLOSE_ALL" 1 "POWERED_CLOSURE_REQUEST_REASON_RKE" 0 "POWERED_CLOSURE_REQUEST_REASON_NONE" ;
VAL_ 505 VCSEC_rearLeftRequestReason 7 "POWERED_CLOSURE_REQUEST_TAP_TO_OPEN" 6 "POWERED_CLOSURE_REQUEST_REASON_UI_REQUEST" 5 "POWERED_CLOSURE_REQUEST_UI_STOP_ALL" 4 "POWERED_CLOSURE_REQUEST_KEYFOB_UNLOCK_OPEN" 3 "POWERED_CLOSURE_REQUEST_REASON_AUTO_PRESENT" 2 "POWERED_CLOSURE_REQUEST_REASON_CLOSE_ALL" 1 "POWERED_CLOSURE_REQUEST_REASON_RKE" 0 "POWERED_CLOSURE_REQUEST_REASON_NONE" ;
VAL_ 505 VCSEC_rearRightRequestReason 7 "POWERED_CLOSURE_REQUEST_TAP_TO_OPEN" 6 "POWERED_CLOSURE_REQUEST_REASON_UI_REQUEST" 5 "POWERED_CLOSURE_REQUEST_UI_STOP_ALL" 4 "POWERED_CLOSURE_REQUEST_KEYFOB_UNLOCK_OPEN" 3 "POWERED_CLOSURE_REQUEST_REASON_AUTO_PRESENT" 2 "POWERED_CLOSURE_REQUEST_REASON_CLOSE_ALL" 1 "POWERED_CLOSURE_REQUEST_REASON_RKE" 0 "POWERED_CLOSURE_REQUEST_REASON_NONE" ;
VAL_ 505 VCSEC_rearTrunkRequestReason 7 "POWERED_CLOSURE_REQUEST_TAP_TO_OPEN" 6 "POWERED_CLOSURE_REQUEST_REASON_UI_REQUEST" 5 "POWERED_CLOSURE_REQUEST_UI_STOP_ALL" 4 "POWERED_CLOSURE_REQUEST_KEYFOB_UNLOCK_OPEN" 3 "POWERED_CLOSURE_REQUEST_REASON_AUTO_PRESENT" 2 "POWERED_CLOSURE_REQUEST_REASON_CLOSE_ALL" 1 "POWERED_CLOSURE_REQUEST_REASON_RKE" 0 "POWERED_CLOSURE_REQUEST_REASON_NONE" ;
VAL_ 505 VCSEC_driveAttemptedWithoutAuth 10 "SHOW_B_PILLAR_NFC_CARD_TAP" 9 "SHOW_CENTER_NFC_CARD_TAP" 8 "SHOW_BRING_PHONE_CLOSER_BPILLAR_VARIANT" 7 "SHOW_BRING_PHONE_CLOSER_CENTER_VARIANT" 6 "SHOW_APP_DOWNLOAD_AND_PHONEKEY_PAIR_BPILLAR_VARIANT" 5 "SHOW_APP_DOWNLOAD_AND_PHONEKEY_PAIR_CENTER_VARIANT" 4 "SHOW_DEVICE_DISCONNECTED_GENERIC_BPILLAR_VARIANT" 3 "SHOW_DEVICE_DISCONNECTED_GENERIC_CENTER_VARIANT" 2 "SHOW_DEVICE_DISCONNECTED_IOS_BPILLAR_VARIANT" 1 "SHOW_DEVICE_DISCONNECTED_IOS_CENTER_VARIANT" 0 "NO_NFC_POPUP_DESIRED" ;
VAL_ 505 VCSEC_closeAllStatus 2 "CLOSEALL_STATE_CANCELABLE" 1 "CLOSEALL_STATE_AVAILABLE" 0 "CLOSEALL_STATE_NOT_AVAILABLE" ;
VAL_ 505 VCSEC_snapshotRequested 15 "EXTERNAL_THERMALS_HIGH" 14 "AUTO_FRUNK_FALSE_BEEP" 13 "AUTO_FRUNK" 12 "AUTHENTICATION_REJECTION_DEVICE_STATIONARY" 11 "AUTO_TRUNK" 10 "RSSI_NN_ALGO_FALSE_POSITIVE" 9 "RSSI_THRESHOLD_ALGO_FALSE_POSITIVE" 8 "RAW_RSSI_ECU_LOG_HANDLE_PULL" 7 "AUTO_TRUNK_FALSE_BEEP" 6 "UNASSIGNED_6" 5 "UNASSIGNED_5" 4 "AUTO_PRESENT_DOOR_CLOSE_WITHOUT_PEDESTRIAN_DETECTED" 3 "AUTO_PRESENT_DOOR_CLOSE_TIMEOUT" 2 "AUTHED_WITHOUT_HANDLE_PULL" 1 "HANDLE_PULL_WITHOUT_AUTH" 0 "NONE" ;
VAL_ 505 VCSEC_chargeportRequestReason 4 "VCSEC_CHARGEPORT_REQUEST_REASON_LONG_PULL_DOOR_HANDLE" 3 "VCSEC_CHARGEPORT_REQUEST_REASON_BLE_CHARGE_HANDLE" 2 "VCSEC_CHARGEPORT_REQUEST_REASON_UHF" 1 "VCSEC_CHARGEPORT_REQUEST_REASON_RKE" 0 "VCSEC_CHARGEPORT_REQUEST_REASON_NONE" ;
VAL_ 505 VCSEC_frontTrunkClosureRequest 6 "POWERED_CLOSURE_REQUEST_CLOSE" 5 "POWERED_CLOSURE_REQUEST_OPEN_REDUCED" 4 "POWERED_CLOSURE_REQUEST_QUICK_OPEN" 3 "POWERED_CLOSURE_REQUEST_OPEN" 2 "POWERED_CLOSURE_REQUEST_STOP" 1 "POWERED_CLOSURE_REQUEST_MOVE" 0 "POWERED_CLOSURE_REQUEST_NONE" ;
VAL_ 505 VCSEC_frontTrunkRequestReason 7 "POWERED_CLOSURE_REQUEST_TAP_TO_OPEN" 6 "POWERED_CLOSURE_REQUEST_REASON_UI_REQUEST" 5 "POWERED_CLOSURE_REQUEST_UI_STOP_ALL" 4 "POWERED_CLOSURE_REQUEST_KEYFOB_UNLOCK_OPEN" 3 "POWERED_CLOSURE_REQUEST_REASON_AUTO_PRESENT" 2 "POWERED_CLOSURE_REQUEST_REASON_CLOSE_ALL" 1 "POWERED_CLOSURE_REQUEST_REASON_RKE" 0 "POWERED_CLOSURE_REQUEST_REASON_NONE" ;
VAL_ 2 VCSEC_activeImmobilizerAuthLevel 3 "IMMOBILIZER_AUTH_LEVEL_MANUAL_RECOVERY" 2 "IMMOBILIZER_AUTH_LEVEL_AUTONOMY" 1 "IMMOBILIZER_AUTH_LEVEL_USER_DRIVE" 0 "IMMOBILIZER_AUTH_LEVEL_NONE" ;
VAL_ 2 VCSEC_smartTrunkLightRequest 3 "VCSEC_LIGHT_REQUEST_TYPE_DIM" 2 "VCSEC_LIGHT_REQUEST_TYPE_BLINK" 1 "VCSEC_LIGHT_REQUEST_TYPE_ON" 0 "VCSEC_LIGHT_REQUEST_TYPE_NONE" ;
VAL_ 2 VCSEC_smartTrunkSoundRequest 2 "VCSEC_SOUND_REQUEST_TYPE_NEAR" 1 "VCSEC_SOUND_REQUEST_TYPE_VICINITY" 0 "VCSEC_SOUND_REQUEST_TYPE_NONE" ;
VAL_ 2 VCSEC_chargeHandleRequestModel 8 "VCSEC_CHARGE_HANDLE_MODEL_SC_CCS2" 7 "VCSEC_CHARGE_HANDLE_MODEL_SC_NACS" 6 "VCSEC_CHARGE_HANDLE_MODEL_WC3_TYPE2" 5 "VCSEC_CHARGE_HANDLE_MODEL_UMC3_TYPE_2" 4 "VCSEC_CHARGE_HANDLE_MODEL_UMC3_GB" 3 "VCSEC_CHARGE_HANDLE_MODEL_UMC3_NACS" 2 "VCSEC_CHARGE_HANDLE_MODEL_WC3_NACS" 0 "VCSEC_CHARGE_HANDLE_MODEL_UNKNOWN" ;
VAL_ 2 VCSEC_mobileToAPRequest 4 "VCSEC_MOBILE_TO_AP_REQUEST_MAX" 2 "VCSEC_MOBILE_TO_AP_REQUEST_DISENGAGE_AUTONOMY" 1 "VCSEC_MOBILE_TO_AP_REQUEST_EMERGENCY_PULL_OVER" 0 "VCSEC_MOBILE_TO_AP_REQUEST_NONE" ;
VAL_ 1850 VC_LVBMS_brickBalancingState1 1 "LVBMS_BALANCING_STATE_ACTIVE" 0 "LVBMS_BALANCING_STATE_INACTIVE" ;
VAL_ 1850 VC_LVBMS_brickBalancingState2 1 "LVBMS_BALANCING_STATE_ACTIVE" 0 "LVBMS_BALANCING_STATE_INACTIVE" ;
VAL_ 1850 VC_LVBMS_brickBalancingState3 1 "LVBMS_BALANCING_STATE_ACTIVE" 0 "LVBMS_BALANCING_STATE_INACTIVE" ;
VAL_ 1850 VC_LVBMS_brickBalancingState4 1 "LVBMS_BALANCING_STATE_ACTIVE" 0 "LVBMS_BALANCING_STATE_INACTIVE" ;
VAL_ 1655 VC_LVBMS_ECPAState 3 "LVBMS_ECPA_STATE_SNA" 2 "LVBMS_ECPA_STATE_INVALID" 1 "LVBMS_ECPA_STATE_CLOSED" 0 "LVBMS_ECPA_STATE_OPEN" ;
VAL_ 1655 VC_LVBMS_MOSState 3 "LVBMS_MOS_STATE_SNA" 2 "LVBMS_MOS_STATE_INVALID" 1 "LVBMS_MOS_STATE_CLOSED" 0 "LVBMS_MOS_STATE_OPEN" ;
VAL_ 1655 VC_LVBMS_VehicleState 3 "LVBMS_VEHICLE_STATE_OFF" 2 "LVBMS_VEHICLE_STATE_CONDITIONING" 1 "LVBMS_VEHICLE_STATE_ACCESSORY" 0 "LVBMS_VEHICLE_STATE_DRIVE" ;
VAL_ 1655 VC_LVBMS_LINWakeDisabled 1 "LVBMS_LIN_WAKE_DISABLED" 0 "LVBMS_LIN_WAKE_ENABLED" ;
VAL_ 1655 VC_LVBMS_chargeType 4 "LVBMS_CHARGE_SNA" 3 "LVBMS_CHARGE_COMPLETE" 2 "LVBMS_CHARGE_CONSTANT_VOLTAGE" 1 "LVBMS_CHARGE_CONSTANT_CURRENT" 0 "LVBMS_CHARGE_UNDEFINED" ;
VAL_ 1816 VC_LVBMS_staticSOCCorrection 1 "LVBMS_CORRECTION_STATE_ACTIVE" 0 "LVBMS_CORRECTION_STATE_INACTIVE" ;
VAL_ 1816 VC_LVBMS_dynamicSOCCorrection 1 "LVBMS_CORRECTION_STATE_ACTIVE" 0 "LVBMS_CORRECTION_STATE_INACTIVE" ;
VAL_ 1816 VC_LVBMS_brakeTelltale 2 "DI_BRAKE_TELLTALE_OFF" 1 "DI_BRAKE_TELLTALE_YELLOW" 0 "DI_BRAKE_TELLTALE_RED" ;
